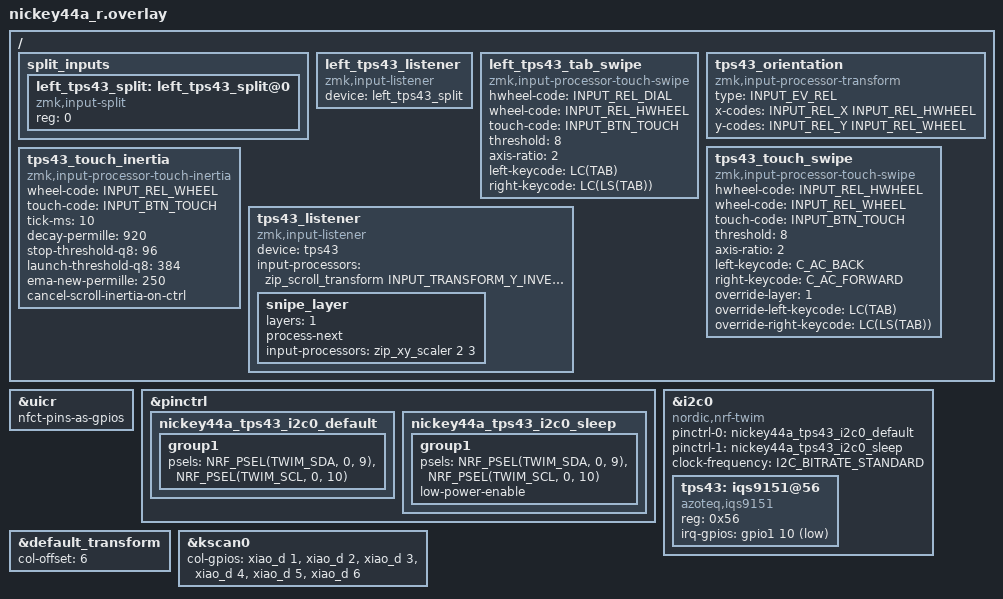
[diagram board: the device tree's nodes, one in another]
#include "nickey44a.dtsi"
#include <input/processors.dtsi>
#include <dt-bindings/gpio/gpio.h>
#include <dt-bindings/pinctrl/nrf-pinctrl.h>
#include <dt-bindings/zmk/input_transform.h>
#include <dt-bindings/zmk/keys.h>
#include <zephyr/dt-bindings/input/input-event-codes.h>

/*
 * yuPad43 (IQS9151) wiring:
 *   SDA = XIAO NFC1/P0.09
 *   SCL = XIAO NFC2/P0.10
 *   RDY = XIAO P1.10 (active-low)
 *   RST = not used (driver resets over I2C)
 */

&uicr {
    nfct-pins-as-gpios;
};

&pinctrl {
    nickey44a_tps43_i2c0_default: nickey44a_tps43_i2c0_default {
        group1 {
            psels = <NRF_PSEL(TWIM_SDA, 0, 9)>,
                    <NRF_PSEL(TWIM_SCL, 0, 10)>;
        };
    };

    nickey44a_tps43_i2c0_sleep: nickey44a_tps43_i2c0_sleep {
        group1 {
            psels = <NRF_PSEL(TWIM_SDA, 0, 9)>,
                    <NRF_PSEL(TWIM_SCL, 0, 10)>;
            low-power-enable;
        };
    };
};

/ {
    split_inputs {
        #address-cells = <1>;
        #size-cells = <0>;

        left_tps43_split: left_tps43_split@0 {
            compatible = "zmk,input-split";
            reg = <0>;
        };
    };

    left_tps43_listener: left_tps43_listener {
        compatible = "zmk,input-listener";
        device = <&left_tps43_split>;
    };

    left_tps43_tab_swipe: left_tps43_tab_swipe {
        compatible = "zmk,input-processor-touch-swipe";
        #input-processor-cells = <0>;
        hwheel-code = <INPUT_REL_DIAL>;
        wheel-code = <INPUT_REL_HWHEEL>;
        touch-code = <INPUT_BTN_TOUCH>;
        threshold = <8>;
        axis-ratio = <2>;
        /* Measured left pad: physical right swipe produces negative DIAL. */
        left-keycode = <LC(TAB)>;
        right-keycode = <LC(LS(TAB))>;
    };

    tps43_orientation: tps43_orientation {
        compatible = "zmk,input-processor-transform";
        #input-processor-cells = <1>;
        type = <INPUT_EV_REL>;
        x-codes = <INPUT_REL_X INPUT_REL_HWHEEL>;
        y-codes = <INPUT_REL_Y INPUT_REL_WHEEL>;
    };

    tps43_touch_swipe: tps43_touch_swipe {
        compatible = "zmk,input-processor-touch-swipe";
        #input-processor-cells = <0>;
        hwheel-code = <INPUT_REL_HWHEEL>;
        wheel-code = <INPUT_REL_WHEEL>;
        touch-code = <INPUT_BTN_TOUCH>;
        threshold = <8>;
        axis-ratio = <2>;
        left-keycode = <C_AC_BACK>;
        right-keycode = <C_AC_FORWARD>;
        override-layer = <1>;
        /* Physical right swipe is negative after orientation correction. */
        override-left-keycode = <LC(TAB)>;
        override-right-keycode = <LC(LS(TAB))>;
    };

    tps43_touch_inertia: tps43_touch_inertia {
        compatible = "zmk,input-processor-touch-inertia";
        #input-processor-cells = <0>;
        wheel-code = <INPUT_REL_WHEEL>;
        touch-code = <INPUT_BTN_TOUCH>;
        tick-ms = <10>;
        decay-permille = <920>;
        stop-threshold-q8 = <96>;
        launch-threshold-q8 = <384>;
        ema-new-permille = <250>;
        cancel-scroll-inertia-on-ctrl;
    };

    tps43_listener: tps43_listener {
        compatible = "zmk,input-listener";
        device = <&tps43>;
        /* yuPad43: orientation is set by CONFIG_INPUT_IQS9151_ROTATE_*.
         * TPS43-only processors (orientation/touch-swipe/touch-inertia) need
         * BTN_TOUCH, which the IQS9151 driver does not send, so they are off. */
        /* Two-finger scroll: finger down = page scrolls down. */
        input-processors = <&zip_scroll_transform INPUT_TRANSFORM_Y_INVERT>;

        snipe_layer {
            layers = <1>;
            process-next;
            input-processors = <&zip_xy_scaler 2 3>;
        };
    };
};

&i2c0 {
    status = "okay";
    compatible = "nordic,nrf-twim";
    pinctrl-0 = <&nickey44a_tps43_i2c0_default>;
    pinctrl-1 = <&nickey44a_tps43_i2c0_sleep>;
    pinctrl-names = "default", "sleep";
    clock-frequency = <I2C_BITRATE_STANDARD>;
    #address-cells = <1>;
    #size-cells = <0>;

    tps43: iqs9151@56 {
        compatible = "azoteq,iqs9151";
        reg = <0x56>;
        status = "okay";
        irq-gpios = <&gpio1 10 (GPIO_ACTIVE_LOW | GPIO_PULL_UP)>;
    };
};

&default_transform {
    col-offset = <6>;
};

&kscan0 {
        col-gpios
            = <&xiao_d 1 GPIO_ACTIVE_HIGH>
            , <&xiao_d 2 GPIO_ACTIVE_HIGH>
            , <&xiao_d 3 GPIO_ACTIVE_HIGH>
            , <&xiao_d 4 GPIO_ACTIVE_HIGH>
            , <&xiao_d 5 GPIO_ACTIVE_HIGH>
            , <&xiao_d 6 GPIO_ACTIVE_HIGH>
            ;
};
